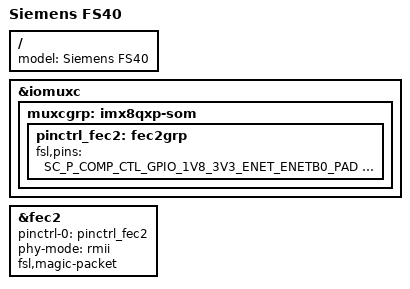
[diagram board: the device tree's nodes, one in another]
// SPDX-License-Identifier: GPL-2.0+
/*
 * Copyright 2019 Siemens AG
 */

#include "imx8-capricorn.dtsi"

/ {
	model = "Siemens FS40";
};

&iomuxc {
	muxcgrp: imx8qxp-som {
		pinctrl_fec2: fec2grp {
			fsl,pins = <
				SC_P_COMP_CTL_GPIO_1V8_3V3_ENET_ENETB0_PAD	0x000014a0
				SC_P_COMP_CTL_GPIO_1V8_3V3_ENET_ENETB1_PAD	0x000014a0
				SC_P_COMP_CTL_GPIO_1V8_3V3_GPIORHB_PAD		0x000514a0

				SC_P_ENET0_MDC_CONN_ENET1_MDC			0x00000060
				SC_P_ENET0_MDIO_CONN_ENET1_MDIO			0x00000060

				SC_P_ESAI0_FSR_CONN_ENET1_RCLK50M_IN		0x00000060
				SC_P_SPDIF0_RX_CONN_ENET1_RGMII_RXD0		0x00000060
				SC_P_ESAI0_TX3_RX2_CONN_ENET1_RGMII_RXD1	0x00000060
				SC_P_ESAI0_TX2_RX3_CONN_ENET1_RMII_RX_ER	0x00000060
				SC_P_SPDIF0_TX_CONN_ENET1_RGMII_RX_CTL		0x00000060
				SC_P_ESAI0_TX4_RX1_CONN_ENET1_RGMII_TXD0	0x00000060
				SC_P_ESAI0_TX5_RX0_CONN_ENET1_RGMII_TXD1	0x00000060
				SC_P_ESAI0_SCKR_CONN_ENET1_RGMII_TX_CTL		0x00000060
			>;
		};
	};
};

&fec2 {
	pinctrl-names = "default";
	pinctrl-0 = <&pinctrl_fec2>;
	phy-mode = "rmii";

	fsl,magic-packet;
	status = "okay";
};
